# ESP32-H4 register map
Vendor: ESPRESSIF SYSTEMS (SHANGHAI) CO., LTD.; Series: ESP32 H-Series; File version: 1
CPU: RV32IMAC r0p0, little endian, no MPU, no FPU, 0 interrupt priority bits
Address unit: 32 bits
Registers are 32-bit, read-write, reset 0x0 unless marked. A register's access mark holds for its fields unless they carry their own. Offsets are from the block's base; [hi:lo] are bit positions; {n}, {i} and the like mark numbered series.

## TEE (part 1 of 2) — TEE Peripheral
Base 0x6009F000
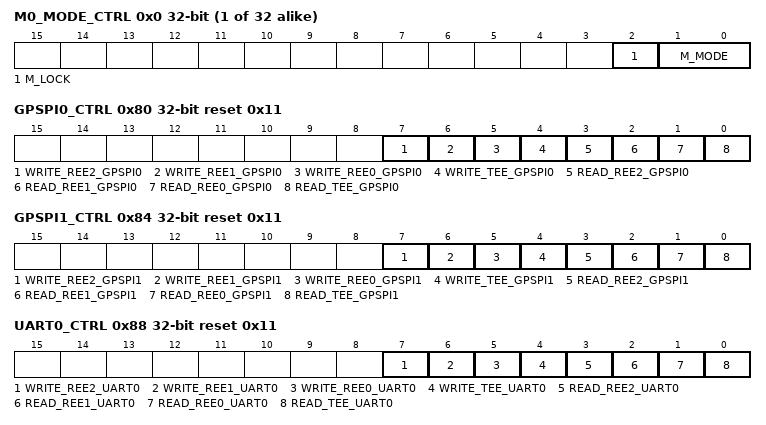
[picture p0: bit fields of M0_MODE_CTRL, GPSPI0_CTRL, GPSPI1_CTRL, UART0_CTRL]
{0x0+4i} M{i}_MODE_CTRL (i=0..31) — TEE mode control register
  [2] M_LOCK — Set 1 to lock m0 tee configuration
  [1:0] M_MODE — Configures M%s security level mode.\\ 0: tee_mode \\ 1: ree_mode0 \\ 2: ree_mode1 \\ 3: ree_mode2 \\
0x80 GPSPI0_CTRL reset 0x11 — gpspi0 read/write control register
  [7] WRITE_REE2_GPSPI0 — Configures gpspi0 registers write permission in ree2 mode.\\ 0: can not be write \\ 1: can be write \\
  [6] WRITE_REE1_GPSPI0 — Configures gpspi0 registers write permission in ree1 mode.\\ 0: can not be write \\ 1: can be write \\
  [5] WRITE_REE0_GPSPI0 — Configures gpspi0 registers write permission in ree0 mode.\\ 0: can not be write \\ 1: can be write \\
  [4] WRITE_TEE_GPSPI0 — Configures gpspi0 registers write permission in tee mode.\\ 0: can not be write \\ 1: can be write \\
  [3] READ_REE2_GPSPI0 — Configures gpspi0 registers read permission in ree2 mode.\\ 0: can not be read \\ 1: can be read \\
  [2] READ_REE1_GPSPI0 — Configures gpspi0 registers read permission in ree1 mode.\\ 0: can not be read \\ 1: can be read \\
  [1] READ_REE0_GPSPI0 — Configures gpspi0 registers read permission in ree0 mode.\\ 0: can not be read \\ 1: can be read \\
  [0] READ_TEE_GPSPI0 — Configures gpspi0 registers read permission in tee mode.\\ 0: can not be read \\ 1: can be read \\
0x84 GPSPI1_CTRL reset 0x11 — gpspi1 read/write control register
  [7] WRITE_REE2_GPSPI1 — Configures gpspi1 registers write permission in ree2 mode.\\ 0: can not be write \\ 1: can be write \\
  [6] WRITE_REE1_GPSPI1 — Configures gpspi1 registers write permission in ree1 mode.\\ 0: can not be write \\ 1: can be write \\
  [5] WRITE_REE0_GPSPI1 — Configures gpspi1 registers write permission in ree0 mode.\\ 0: can not be write \\ 1: can be write \\
  [4] WRITE_TEE_GPSPI1 — Configures gpspi1 registers write permission in tee mode.\\ 0: can not be write \\ 1: can be write \\
  [3] READ_REE2_GPSPI1 — Configures gpspi1 registers read permission in ree2 mode.\\ 0: can not be read \\ 1: can be read \\
  [2] READ_REE1_GPSPI1 — Configures gpspi1 registers read permission in ree1 mode.\\ 0: can not be read \\ 1: can be read \\
  [1] READ_REE0_GPSPI1 — Configures gpspi1 registers read permission in ree0 mode.\\ 0: can not be read \\ 1: can be read \\
  [0] READ_TEE_GPSPI1 — Configures gpspi1 registers read permission in tee mode.\\ 0: can not be read \\ 1: can be read \\
0x88 UART0_CTRL reset 0x11 — uart0 read/write control register
  [7] WRITE_REE2_UART0 — Configures uart0 registers write permission in ree2 mode.\\ 0: can not be write \\ 1: can be write \\
  [6] WRITE_REE1_UART0 — Configures uart0 registers write permission in ree1 mode.\\ 0: can not be write \\ 1: can be write \\
  [5] WRITE_REE0_UART0 — Configures uart0 registers write permission in ree0 mode.\\ 0: can not be write \\ 1: can be write \\
  [4] WRITE_TEE_UART0 — Configures uart0 registers write permission in tee mode.\\ 0: can not be write \\ 1: can be write \\
  [3] READ_REE2_UART0 — Configures uart0 registers read permission in ree2 mode.\\ 0: can not be read \\ 1: can be read \\
  [2] READ_REE1_UART0 — Configures uart0 registers read permission in ree1 mode.\\ 0: can not be read \\ 1: can be read \\
  [1] READ_REE0_UART0 — Configures uart0 registers read permission in ree0 mode.\\ 0: can not be read \\ 1: can be read \\
  [0] READ_TEE_UART0 — Configures uart0 registers read permission in tee mode.\\ 0: can not be read \\ 1: can be read \\
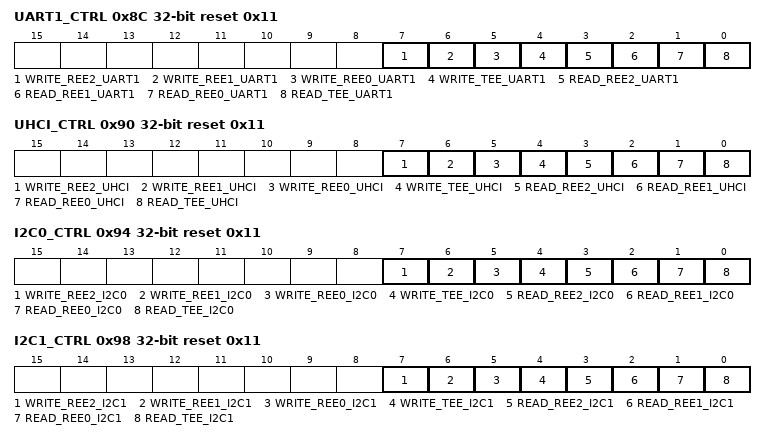
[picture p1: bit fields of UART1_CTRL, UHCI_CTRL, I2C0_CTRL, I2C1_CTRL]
0x8C UART1_CTRL reset 0x11 — uart1 read/write control register
  [7] WRITE_REE2_UART1 — Configures uart1 registers write permission in ree2 mode.\\ 0: can not be write \\ 1: can be write \\
  [6] WRITE_REE1_UART1 — Configures uart1 registers write permission in ree1 mode.\\ 0: can not be write \\ 1: can be write \\
  [5] WRITE_REE0_UART1 — Configures uart1 registers write permission in ree0 mode.\\ 0: can not be write \\ 1: can be write \\
  [4] WRITE_TEE_UART1 — Configures uart1 registers write permission in tee mode.\\ 0: can not be write \\ 1: can be write \\
  [3] READ_REE2_UART1 — Configures uart1 registers read permission in ree2 mode.\\ 0: can not be read \\ 1: can be read \\
  [2] READ_REE1_UART1 — Configures uart1 registers read permission in ree1 mode.\\ 0: can not be read \\ 1: can be read \\
  [1] READ_REE0_UART1 — Configures uart1 registers read permission in ree0 mode.\\ 0: can not be read \\ 1: can be read \\
  [0] READ_TEE_UART1 — Configures uart1 registers read permission in tee mode.\\ 0: can not be read \\ 1: can be read \\
0x90 UHCI_CTRL reset 0x11 — uhci read/write control register
  [7] WRITE_REE2_UHCI — Configures uhci registers write permission in ree2 mode.\\ 0: can not be write \\ 1: can be write \\
  [6] WRITE_REE1_UHCI — Configures uhci registers write permission in ree1 mode.\\ 0: can not be write \\ 1: can be write \\
  [5] WRITE_REE0_UHCI — Configures uhci registers write permission in ree0 mode.\\ 0: can not be write \\ 1: can be write \\
  [4] WRITE_TEE_UHCI — Configures uhci registers write permission in tee mode.\\ 0: can not be write \\ 1: can be write \\
  [3] READ_REE2_UHCI — Configures uhci registers read permission in ree2 mode.\\ 0: can not be read \\ 1: can be read \\
  [2] READ_REE1_UHCI — Configures uhci registers read permission in ree1 mode.\\ 0: can not be read \\ 1: can be read \\
  [1] READ_REE0_UHCI — Configures uhci registers read permission in ree0 mode.\\ 0: can not be read \\ 1: can be read \\
  [0] READ_TEE_UHCI — Configures uhci registers read permission in tee mode.\\ 0: can not be read \\ 1: can be read \\
0x94 I2C0_CTRL reset 0x11 — i2c0 read/write control register
  [7] WRITE_REE2_I2C0 — Configures i2c0 registers write permission in ree2 mode.\\ 0: can not be write \\ 1: can be write \\
  [6] WRITE_REE1_I2C0 — Configures i2c0 registers write permission in ree1 mode.\\ 0: can not be write \\ 1: can be write \\
  [5] WRITE_REE0_I2C0 — Configures i2c0 registers write permission in ree0 mode.\\ 0: can not be write \\ 1: can be write \\
  [4] WRITE_TEE_I2C0 — Configures i2c0 registers write permission in tee mode.\\ 0: can not be write \\ 1: can be write \\
  [3] READ_REE2_I2C0 — Configures i2c0 registers read permission in ree2 mode.\\ 0: can not be read \\ 1: can be read \\
  [2] READ_REE1_I2C0 — Configures i2c0 registers read permission in ree1 mode.\\ 0: can not be read \\ 1: can be read \\
  [1] READ_REE0_I2C0 — Configures i2c0 registers read permission in ree0 mode.\\ 0: can not be read \\ 1: can be read \\
  [0] READ_TEE_I2C0 — Configures i2c0 registers read permission in tee mode.\\ 0: can not be read \\ 1: can be read \\
0x98 I2C1_CTRL reset 0x11 — i2c1 read/write control register
  [7] WRITE_REE2_I2C1 — Configures i2c1 registers write permission in ree2 mode.\\ 0: can not be write \\ 1: can be write \\
  [6] WRITE_REE1_I2C1 — Configures i2c1 registers write permission in ree1 mode.\\ 0: can not be write \\ 1: can be write \\
  [5] WRITE_REE0_I2C1 — Configures i2c1 registers write permission in ree0 mode.\\ 0: can not be write \\ 1: can be write \\
  [4] WRITE_TEE_I2C1 — Configures i2c1 registers write permission in tee mode.\\ 0: can not be write \\ 1: can be write \\
  [3] READ_REE2_I2C1 — Configures i2c1 registers read permission in ree2 mode.\\ 0: can not be read \\ 1: can be read \\
  [2] READ_REE1_I2C1 — Configures i2c1 registers read permission in ree1 mode.\\ 0: can not be read \\ 1: can be read \\
  [1] READ_REE0_I2C1 — Configures i2c1 registers read permission in ree0 mode.\\ 0: can not be read \\ 1: can be read \\
  [0] READ_TEE_I2C1 — Configures i2c1 registers read permission in tee mode.\\ 0: can not be read \\ 1: can be read \\
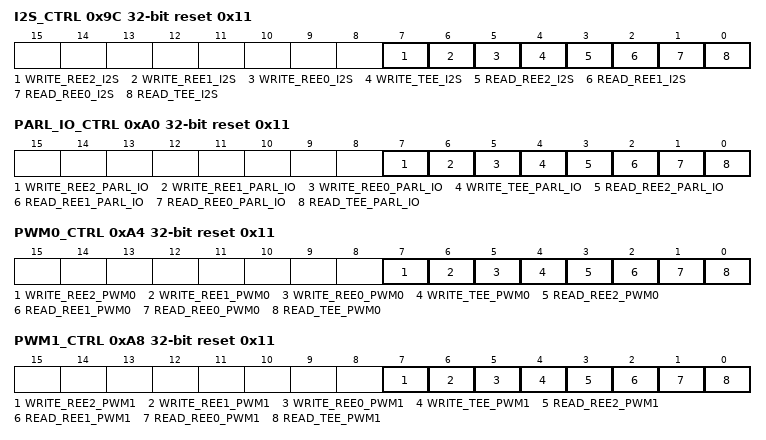
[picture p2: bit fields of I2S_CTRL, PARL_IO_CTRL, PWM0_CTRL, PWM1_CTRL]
0x9C I2S_CTRL reset 0x11 — i2s read/write control register
  [7] WRITE_REE2_I2S — Configures i2s registers write permission in ree2 mode.\\ 0: can not be write \\ 1: can be write \\
  [6] WRITE_REE1_I2S — Configures i2s registers write permission in ree1 mode.\\ 0: can not be write \\ 1: can be write \\
  [5] WRITE_REE0_I2S — Configures i2s registers write permission in ree0 mode.\\ 0: can not be write \\ 1: can be write \\
  [4] WRITE_TEE_I2S — Configures i2s registers write permission in tee mode.\\ 0: can not be write \\ 1: can be write \\
  [3] READ_REE2_I2S — Configures i2s registers read permission in ree2 mode.\\ 0: can not be read \\ 1: can be read \\
  [2] READ_REE1_I2S — Configures i2s registers read permission in ree1 mode.\\ 0: can not be read \\ 1: can be read \\
  [1] READ_REE0_I2S — Configures i2s registers read permission in ree0 mode.\\ 0: can not be read \\ 1: can be read \\
  [0] READ_TEE_I2S — Configures i2s registers read permission in tee mode.\\ 0: can not be read \\ 1: can be read \\
0xA0 PARL_IO_CTRL reset 0x11 — parl_io read/write control register
  [7] WRITE_REE2_PARL_IO — Configures parl_io registers write permission in ree2 mode.\\ 0: can not be write \\ 1: can be write \\
  [6] WRITE_REE1_PARL_IO — Configures parl_io registers write permission in ree1 mode.\\ 0: can not be write \\ 1: can be write \\
  [5] WRITE_REE0_PARL_IO — Configures parl_io registers write permission in ree0 mode.\\ 0: can not be write \\ 1: can be write \\
  [4] WRITE_TEE_PARL_IO — Configures parl_io registers write permission in tee mode.\\ 0: can not be write \\ 1: can be write \\
  [3] READ_REE2_PARL_IO — Configures parl_io registers read permission in ree2 mode.\\ 0: can not be read \\ 1: can be read \\
  [2] READ_REE1_PARL_IO — Configures parl_io registers read permission in ree1 mode.\\ 0: can not be read \\ 1: can be read \\
  [1] READ_REE0_PARL_IO — Configures parl_io registers read permission in ree0 mode.\\ 0: can not be read \\ 1: can be read \\
  [0] READ_TEE_PARL_IO — Configures parl_io registers read permission in tee mode.\\ 0: can not be read \\ 1: can be read \\
0xA4 PWM0_CTRL reset 0x11 — pwm0 read/write control register
  [7] WRITE_REE2_PWM0 — Configures pwm0 registers write permission in ree2 mode.\\ 0: can not be write \\ 1: can be write \\
  [6] WRITE_REE1_PWM0 — Configures pwm0 registers write permission in ree1 mode.\\ 0: can not be write \\ 1: can be write \\
  [5] WRITE_REE0_PWM0 — Configures pwm0 registers write permission in ree0 mode.\\ 0: can not be write \\ 1: can be write \\
  [4] WRITE_TEE_PWM0 — Configures pwm0 registers write permission in tee mode.\\ 0: can not be write \\ 1: can be write \\
  [3] READ_REE2_PWM0 — Configures pwm0 registers read permission in ree2 mode.\\ 0: can not be read \\ 1: can be read \\
  [2] READ_REE1_PWM0 — Configures pwm0 registers read permission in ree1 mode.\\ 0: can not be read \\ 1: can be read \\
  [1] READ_REE0_PWM0 — Configures pwm0 registers read permission in ree0 mode.\\ 0: can not be read \\ 1: can be read \\
  [0] READ_TEE_PWM0 — Configures pwm0 registers read permission in tee mode.\\ 0: can not be read \\ 1: can be read \\
0xA8 PWM1_CTRL reset 0x11 — pwm1 read/write control register
  [7] WRITE_REE2_PWM1 — Configures pwm1 registers write permission in ree2 mode.\\ 0: can not be write \\ 1: can be write \\
  [6] WRITE_REE1_PWM1 — Configures pwm1 registers write permission in ree1 mode.\\ 0: can not be write \\ 1: can be write \\
  [5] WRITE_REE0_PWM1 — Configures pwm1 registers write permission in ree0 mode.\\ 0: can not be write \\ 1: can be write \\
  [4] WRITE_TEE_PWM1 — Configures pwm1 registers write permission in tee mode.\\ 0: can not be write \\ 1: can be write \\
  [3] READ_REE2_PWM1 — Configures pwm1 registers read permission in ree2 mode.\\ 0: can not be read \\ 1: can be read \\
  [2] READ_REE1_PWM1 — Configures pwm1 registers read permission in ree1 mode.\\ 0: can not be read \\ 1: can be read \\
  [1] READ_REE0_PWM1 — Configures pwm1 registers read permission in ree0 mode.\\ 0: can not be read \\ 1: can be read \\
  [0] READ_TEE_PWM1 — Configures pwm1 registers read permission in tee mode.\\ 0: can not be read \\ 1: can be read \\
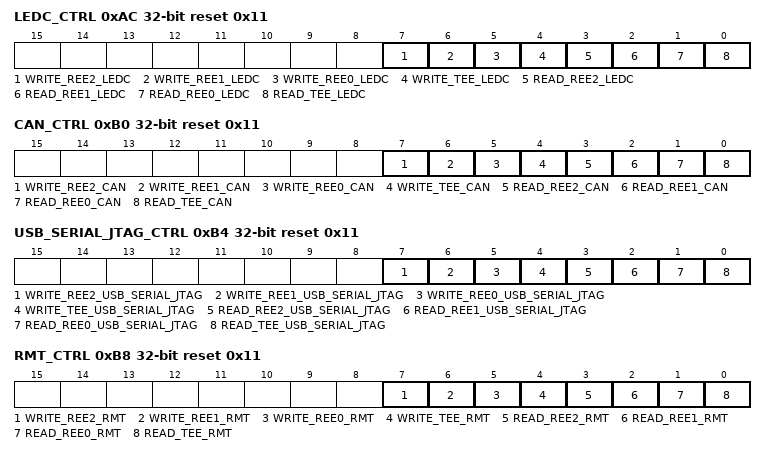
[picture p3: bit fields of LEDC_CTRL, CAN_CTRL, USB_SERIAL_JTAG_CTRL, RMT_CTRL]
0xAC LEDC_CTRL reset 0x11 — ledc read/write control register
  [7] WRITE_REE2_LEDC — Configures ledc registers write permission in ree2 mode.\\ 0: can not be write \\ 1: can be write \\
  [6] WRITE_REE1_LEDC — Configures ledc registers write permission in ree1 mode.\\ 0: can not be write \\ 1: can be write \\
  [5] WRITE_REE0_LEDC — Configures ledc registers write permission in ree0 mode.\\ 0: can not be write \\ 1: can be write \\
  [4] WRITE_TEE_LEDC — Configures ledc registers write permission in tee mode.\\ 0: can not be write \\ 1: can be write \\
  [3] READ_REE2_LEDC — Configures ledc registers read permission in ree2 mode.\\ 0: can not be read \\ 1: can be read \\
  [2] READ_REE1_LEDC — Configures ledc registers read permission in ree1 mode.\\ 0: can not be read \\ 1: can be read \\
  [1] READ_REE0_LEDC — Configures ledc registers read permission in ree0 mode.\\ 0: can not be read \\ 1: can be read \\
  [0] READ_TEE_LEDC — Configures ledc registers read permission in tee mode.\\ 0: can not be read \\ 1: can be read \\
0xB0 CAN_CTRL reset 0x11 — can read/write control register
  [7] WRITE_REE2_CAN — Configures can registers write permission in ree2 mode.\\ 0: can not be write \\ 1: can be write \\
  [6] WRITE_REE1_CAN — Configures can registers write permission in ree1 mode.\\ 0: can not be write \\ 1: can be write \\
  [5] WRITE_REE0_CAN — Configures can registers write permission in ree0 mode.\\ 0: can not be write \\ 1: can be write \\
  [4] WRITE_TEE_CAN — Configures can registers write permission in tee mode.\\ 0: can not be write \\ 1: can be write \\
  [3] READ_REE2_CAN — Configures can registers read permission in ree2 mode.\\ 0: can not be read \\ 1: can be read \\
  [2] READ_REE1_CAN — Configures can registers read permission in ree1 mode.\\ 0: can not be read \\ 1: can be read \\
  [1] READ_REE0_CAN — Configures can registers read permission in ree0 mode.\\ 0: can not be read \\ 1: can be read \\
  [0] READ_TEE_CAN — Configures can registers read permission in tee mode.\\ 0: can not be read \\ 1: can be read \\
0xB4 USB_SERIAL_JTAG_CTRL reset 0x11 — usb_serial_jtag read/write control register
  [7] WRITE_REE2_USB_SERIAL_JTAG — Configures usb_serial_jtag registers write permission in ree2 mode.\\ 0: can not be write \\ 1: can be write \\
  [6] WRITE_REE1_USB_SERIAL_JTAG — Configures usb_serial_jtag registers write permission in ree1 mode.\\ 0: can not be write \\ 1: can be write \\
  [5] WRITE_REE0_USB_SERIAL_JTAG — Configures usb_serial_jtag registers write permission in ree0 mode.\\ 0: can not be write \\ 1: can be write \\
  [4] WRITE_TEE_USB_SERIAL_JTAG — Configures usb_serial_jtag registers write permission in tee mode.\\ 0: can not be write \\ 1: can be write \\
  [3] READ_REE2_USB_SERIAL_JTAG — Configures usb_serial_jtag registers read permission in ree2 mode.\\ 0: can not be read \\ 1: can be read \\
  [2] READ_REE1_USB_SERIAL_JTAG — Configures usb_serial_jtag registers read permission in ree1 mode.\\ 0: can not be read \\ 1: can be read \\
  [1] READ_REE0_USB_SERIAL_JTAG — Configures usb_serial_jtag registers read permission in ree0 mode.\\ 0: can not be read \\ 1: can be read \\
  [0] READ_TEE_USB_SERIAL_JTAG — Configures usb_serial_jtag registers read permission in tee mode.\\ 0: can not be read \\ 1: can be read \\
0xB8 RMT_CTRL reset 0x11 — rmt read/write control register
  [7] WRITE_REE2_RMT — Configures rmt registers write permission in ree2 mode.\\ 0: can not be write \\ 1: can be write \\
  [6] WRITE_REE1_RMT — Configures rmt registers write permission in ree1 mode.\\ 0: can not be write \\ 1: can be write \\
  [5] WRITE_REE0_RMT — Configures rmt registers write permission in ree0 mode.\\ 0: can not be write \\ 1: can be write \\
  [4] WRITE_TEE_RMT — Configures rmt registers write permission in tee mode.\\ 0: can not be write \\ 1: can be write \\
  [3] READ_REE2_RMT — Configures rmt registers read permission in ree2 mode.\\ 0: can not be read \\ 1: can be read \\
  [2] READ_REE1_RMT — Configures rmt registers read permission in ree1 mode.\\ 0: can not be read \\ 1: can be read \\
  [1] READ_REE0_RMT — Configures rmt registers read permission in ree0 mode.\\ 0: can not be read \\ 1: can be read \\
  [0] READ_TEE_RMT — Configures rmt registers read permission in tee mode.\\ 0: can not be read \\ 1: can be read \\
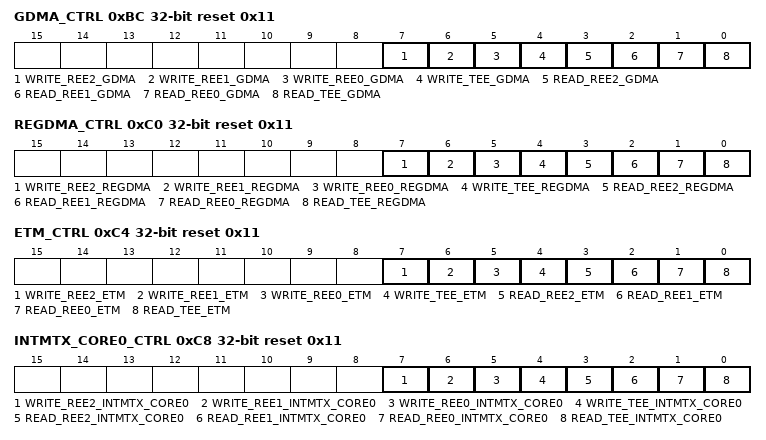
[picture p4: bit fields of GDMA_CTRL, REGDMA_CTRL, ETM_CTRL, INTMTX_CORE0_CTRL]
0xBC GDMA_CTRL reset 0x11 — gdma read/write control register
  [7] WRITE_REE2_GDMA — Configures gdma registers write permission in ree2 mode.\\ 0: can not be write \\ 1: can be write \\
  [6] WRITE_REE1_GDMA — Configures gdma registers write permission in ree1 mode.\\ 0: can not be write \\ 1: can be write \\
  [5] WRITE_REE0_GDMA — Configures gdma registers write permission in ree0 mode.\\ 0: can not be write \\ 1: can be write \\
  [4] WRITE_TEE_GDMA — Configures gdma registers write permission in tee mode.\\ 0: can not be write \\ 1: can be write \\
  [3] READ_REE2_GDMA — Configures gdma registers read permission in ree2 mode.\\ 0: can not be read \\ 1: can be read \\
  [2] READ_REE1_GDMA — Configures gdma registers read permission in ree1 mode.\\ 0: can not be read \\ 1: can be read \\
  [1] READ_REE0_GDMA — Configures gdma registers read permission in ree0 mode.\\ 0: can not be read \\ 1: can be read \\
  [0] READ_TEE_GDMA — Configures gdma registers read permission in tee mode.\\ 0: can not be read \\ 1: can be read \\
0xC0 REGDMA_CTRL reset 0x11 — regdma read/write control register
  [7] WRITE_REE2_REGDMA — Configures regdma registers write permission in ree2 mode.\\ 0: can not be write \\ 1: can be write \\
  [6] WRITE_REE1_REGDMA — Configures regdma registers write permission in ree1 mode.\\ 0: can not be write \\ 1: can be write \\
  [5] WRITE_REE0_REGDMA — Configures regdma registers write permission in ree0 mode.\\ 0: can not be write \\ 1: can be write \\
  [4] WRITE_TEE_REGDMA — Configures regdma registers write permission in tee mode.\\ 0: can not be write \\ 1: can be write \\
  [3] READ_REE2_REGDMA — Configures regdma registers read permission in ree2 mode.\\ 0: can not be read \\ 1: can be read \\
  [2] READ_REE1_REGDMA — Configures regdma registers read permission in ree1 mode.\\ 0: can not be read \\ 1: can be read \\
  [1] READ_REE0_REGDMA — Configures regdma registers read permission in ree0 mode.\\ 0: can not be read \\ 1: can be read \\
  [0] READ_TEE_REGDMA — Configures regdma registers read permission in tee mode.\\ 0: can not be read \\ 1: can be read \\
0xC4 ETM_CTRL reset 0x11 — etm read/write control register
  [7] WRITE_REE2_ETM — Configures etm registers write permission in ree2 mode.\\ 0: can not be write \\ 1: can be write \\
  [6] WRITE_REE1_ETM — Configures etm registers write permission in ree1 mode.\\ 0: can not be write \\ 1: can be write \\
  [5] WRITE_REE0_ETM — Configures etm registers write permission in ree0 mode.\\ 0: can not be write \\ 1: can be write \\
  [4] WRITE_TEE_ETM — Configures etm registers write permission in tee mode.\\ 0: can not be write \\ 1: can be write \\
  [3] READ_REE2_ETM — Configures etm registers read permission in ree2 mode.\\ 0: can not be read \\ 1: can be read \\
  [2] READ_REE1_ETM — Configures etm registers read permission in ree1 mode.\\ 0: can not be read \\ 1: can be read \\
  [1] READ_REE0_ETM — Configures etm registers read permission in ree0 mode.\\ 0: can not be read \\ 1: can be read \\
  [0] READ_TEE_ETM — Configures etm registers read permission in tee mode.\\ 0: can not be read \\ 1: can be read \\
0xC8 INTMTX_CORE0_CTRL reset 0x11 — intmtx_core0 read/write control register
  [7] WRITE_REE2_INTMTX_CORE0 — Configures intmtx_core0 registers write permission in ree2 mode.\\ 0: can not be write \\ 1: can be write \\
  [6] WRITE_REE1_INTMTX_CORE0 — Configures intmtx_core0 registers write permission in ree1 mode.\\ 0: can not be write \\ 1: can be write \\
  [5] WRITE_REE0_INTMTX_CORE0 — Configures intmtx_core0 registers write permission in ree0 mode.\\ 0: can not be write \\ 1: can be write \\
  [4] WRITE_TEE_INTMTX_CORE0 — Configures intmtx_core0 registers write permission in tee mode.\\ 0: can not be write \\ 1: can be write \\
  [3] READ_REE2_INTMTX_CORE0 — Configures intmtx_core0 registers read permission in ree2 mode.\\ 0: can not be read \\ 1: can be read \\
  [2] READ_REE1_INTMTX_CORE0 — Configures intmtx_core0 registers read permission in ree1 mode.\\ 0: can not be read \\ 1: can be read \\
  [1] READ_REE0_INTMTX_CORE0 — Configures intmtx_core0 registers read permission in ree0 mode.\\ 0: can not be read \\ 1: can be read \\
  [0] READ_TEE_INTMTX_CORE0 — Configures intmtx_core0 registers read permission in tee mode.\\ 0: can not be read \\ 1: can be read \\
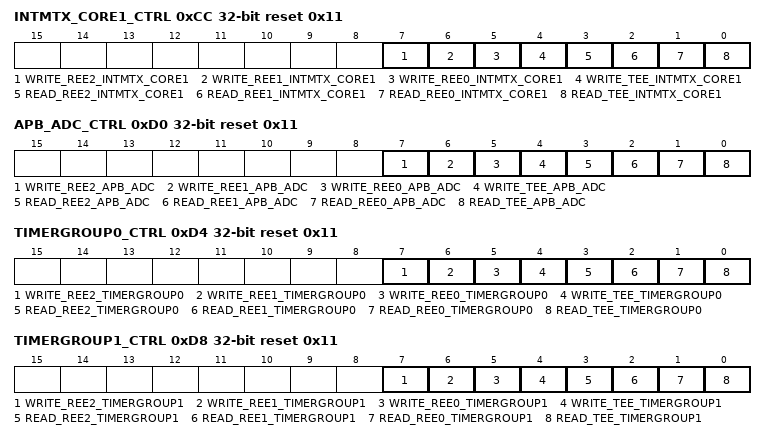
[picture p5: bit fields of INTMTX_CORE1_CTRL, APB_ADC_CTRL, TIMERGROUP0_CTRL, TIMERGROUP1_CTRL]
0xCC INTMTX_CORE1_CTRL reset 0x11 — intmtx_core1 read/write control register
  [7] WRITE_REE2_INTMTX_CORE1 — Configures intmtx_core1 registers write permission in ree2 mode.\\ 0: can not be write \\ 1: can be write \\
  [6] WRITE_REE1_INTMTX_CORE1 — Configures intmtx_core1 registers write permission in ree1 mode.\\ 0: can not be write \\ 1: can be write \\
  [5] WRITE_REE0_INTMTX_CORE1 — Configures intmtx_core1 registers write permission in ree0 mode.\\ 0: can not be write \\ 1: can be write \\
  [4] WRITE_TEE_INTMTX_CORE1 — Configures intmtx_core1 registers write permission in tee mode.\\ 0: can not be write \\ 1: can be write \\
  [3] READ_REE2_INTMTX_CORE1 — Configures intmtx_core1 registers read permission in ree2 mode.\\ 0: can not be read \\ 1: can be read \\
  [2] READ_REE1_INTMTX_CORE1 — Configures intmtx_core1 registers read permission in ree1 mode.\\ 0: can not be read \\ 1: can be read \\
  [1] READ_REE0_INTMTX_CORE1 — Configures intmtx_core1 registers read permission in ree0 mode.\\ 0: can not be read \\ 1: can be read \\
  [0] READ_TEE_INTMTX_CORE1 — Configures intmtx_core1 registers read permission in tee mode.\\ 0: can not be read \\ 1: can be read \\
0xD0 APB_ADC_CTRL reset 0x11 — apb_adc read/write control register
  [7] WRITE_REE2_APB_ADC — Configures apb_adc registers write permission in ree2 mode.\\ 0: can not be write \\ 1: can be write \\
  [6] WRITE_REE1_APB_ADC — Configures apb_adc registers write permission in ree1 mode.\\ 0: can not be write \\ 1: can be write \\
  [5] WRITE_REE0_APB_ADC — Configures apb_adc registers write permission in ree0 mode.\\ 0: can not be write \\ 1: can be write \\
  [4] WRITE_TEE_APB_ADC — Configures apb_adc registers write permission in tee mode.\\ 0: can not be write \\ 1: can be write \\
  [3] READ_REE2_APB_ADC — Configures apb_adc registers read permission in ree2 mode.\\ 0: can not be read \\ 1: can be read \\
  [2] READ_REE1_APB_ADC — Configures apb_adc registers read permission in ree1 mode.\\ 0: can not be read \\ 1: can be read \\
  [1] READ_REE0_APB_ADC — Configures apb_adc registers read permission in ree0 mode.\\ 0: can not be read \\ 1: can be read \\
  [0] READ_TEE_APB_ADC — Configures apb_adc registers read permission in tee mode.\\ 0: can not be read \\ 1: can be read \\
0xD4 TIMERGROUP0_CTRL reset 0x11 — timergroup0 read/write control register
  [7] WRITE_REE2_TIMERGROUP0 — Configures timergroup0 registers write permission in ree2 mode.\\ 0: can not be write \\ 1: can be write \\
  [6] WRITE_REE1_TIMERGROUP0 — Configures timergroup0 registers write permission in ree1 mode.\\ 0: can not be write \\ 1: can be write \\
  [5] WRITE_REE0_TIMERGROUP0 — Configures timergroup0 registers write permission in ree0 mode.\\ 0: can not be write \\ 1: can be write \\
  [4] WRITE_TEE_TIMERGROUP0 — Configures timergroup0 registers write permission in tee mode.\\ 0: can not be write \\ 1: can be write \\
  [3] READ_REE2_TIMERGROUP0 — Configures timergroup0 registers read permission in ree2 mode.\\ 0: can not be read \\ 1: can be read \\
  [2] READ_REE1_TIMERGROUP0 — Configures timergroup0 registers read permission in ree1 mode.\\ 0: can not be read \\ 1: can be read \\
  [1] READ_REE0_TIMERGROUP0 — Configures timergroup0 registers read permission in ree0 mode.\\ 0: can not be read \\ 1: can be read \\
  [0] READ_TEE_TIMERGROUP0 — Configures timergroup0 registers read permission in tee mode.\\ 0: can not be read \\ 1: can be read \\
0xD8 TIMERGROUP1_CTRL reset 0x11 — timergroup1 read/write control register
  [7] WRITE_REE2_TIMERGROUP1 — Configures timergroup1 registers write permission in ree2 mode.\\ 0: can not be write \\ 1: can be write \\
  [6] WRITE_REE1_TIMERGROUP1 — Configures timergroup1 registers write permission in ree1 mode.\\ 0: can not be write \\ 1: can be write \\
  [5] WRITE_REE0_TIMERGROUP1 — Configures timergroup1 registers write permission in ree0 mode.\\ 0: can not be write \\ 1: can be write \\
  [4] WRITE_TEE_TIMERGROUP1 — Configures timergroup1 registers write permission in tee mode.\\ 0: can not be write \\ 1: can be write \\
  [3] READ_REE2_TIMERGROUP1 — Configures timergroup1 registers read permission in ree2 mode.\\ 0: can not be read \\ 1: can be read \\
  [2] READ_REE1_TIMERGROUP1 — Configures timergroup1 registers read permission in ree1 mode.\\ 0: can not be read \\ 1: can be read \\
  [1] READ_REE0_TIMERGROUP1 — Configures timergroup1 registers read permission in ree0 mode.\\ 0: can not be read \\ 1: can be read \\
  [0] READ_TEE_TIMERGROUP1 — Configures timergroup1 registers read permission in tee mode.\\ 0: can not be read \\ 1: can be read \\
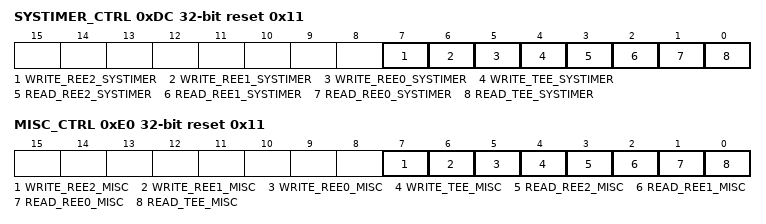
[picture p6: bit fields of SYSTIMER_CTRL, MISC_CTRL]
0xDC SYSTIMER_CTRL reset 0x11 — systimer read/write control register
  [7] WRITE_REE2_SYSTIMER — Configures systimer registers write permission in ree2 mode.\\ 0: can not be write \\ 1: can be write \\
  [6] WRITE_REE1_SYSTIMER — Configures systimer registers write permission in ree1 mode.\\ 0: can not be write \\ 1: can be write \\
  [5] WRITE_REE0_SYSTIMER — Configures systimer registers write permission in ree0 mode.\\ 0: can not be write \\ 1: can be write \\
  [4] WRITE_TEE_SYSTIMER — Configures systimer registers write permission in tee mode.\\ 0: can not be write \\ 1: can be write \\
  [3] READ_REE2_SYSTIMER — Configures systimer registers read permission in ree2 mode.\\ 0: can not be read \\ 1: can be read \\
  [2] READ_REE1_SYSTIMER — Configures systimer registers read permission in ree1 mode.\\ 0: can not be read \\ 1: can be read \\
  [1] READ_REE0_SYSTIMER — Configures systimer registers read permission in ree0 mode.\\ 0: can not be read \\ 1: can be read \\
  [0] READ_TEE_SYSTIMER — Configures systimer registers read permission in tee mode.\\ 0: can not be read \\ 1: can be read \\
0xE0 MISC_CTRL reset 0x11 — misc read/write control register
  [7] WRITE_REE2_MISC — Configures misc registers write permission in ree2 mode.\\ 0: can not be write \\ 1: can be write \\
  [6] WRITE_REE1_MISC — Configures misc registers write permission in ree1 mode.\\ 0: can not be write \\ 1: can be write \\
  [5] WRITE_REE0_MISC — Configures misc registers write permission in ree0 mode.\\ 0: can not be write \\ 1: can be write \\
  [4] WRITE_TEE_MISC — Configures misc registers write permission in tee mode.\\ 0: can not be write \\ 1: can be write \\
  [3] READ_REE2_MISC — Configures misc registers read permission in ree2 mode.\\ 0: can not be read \\ 1: can be read \\
  [2] READ_REE1_MISC — Configures misc registers read permission in ree1 mode.\\ 0: can not be read \\ 1: can be read \\
  [1] READ_REE0_MISC — Configures misc registers read permission in ree0 mode.\\ 0: can not be read \\ 1: can be read \\
  [0] READ_TEE_MISC — Configures misc registers read permission in tee mode.\\ 0: can not be read \\ 1: can be read \\
